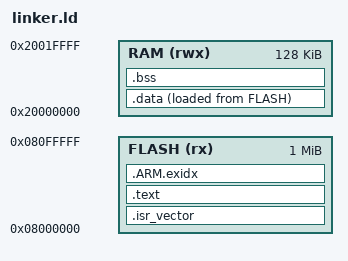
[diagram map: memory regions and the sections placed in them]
/* SPDX-License-Identifier: MIT */
/* Tunuino STM32F407ZGT6: 1 MiB flash, 192 KiB SRAM (128K + 64K CCM).
 * Initial firmware uses only the contiguous 128 KiB SRAM region. */
ENTRY(Reset_Handler)
MEMORY {
  FLASH (rx)  : ORIGIN = 0x08000000, LENGTH = 1024K
  RAM (rwx)   : ORIGIN = 0x20000000, LENGTH = 128K
}
_estack = ORIGIN(RAM) + LENGTH(RAM);
SECTIONS {
  .isr_vector : { KEEP(*(.isr_vector)) } > FLASH
  .text : { *(.text*) *(.rodata*) . = ALIGN(4); } > FLASH
  .ARM.exidx : { *(.ARM.exidx*) } > FLASH
  .data : {
    . = ALIGN(4);
    _sdata = .;
    *(.data*)
    . = ALIGN(4);
    _edata = .;
  } > RAM AT > FLASH
  _sidata = LOADADDR(.data);
  .bss (NOLOAD) : {
    . = ALIGN(4);
    _sbss = .;
    *(.bss*) *(COMMON)
    . = ALIGN(4);
    _ebss = .;
  } > RAM
  /DISCARD/ : { *(.comment*) *(.note*) }
}
ASSERT(_estack > _ebss, "RAM overflow")
